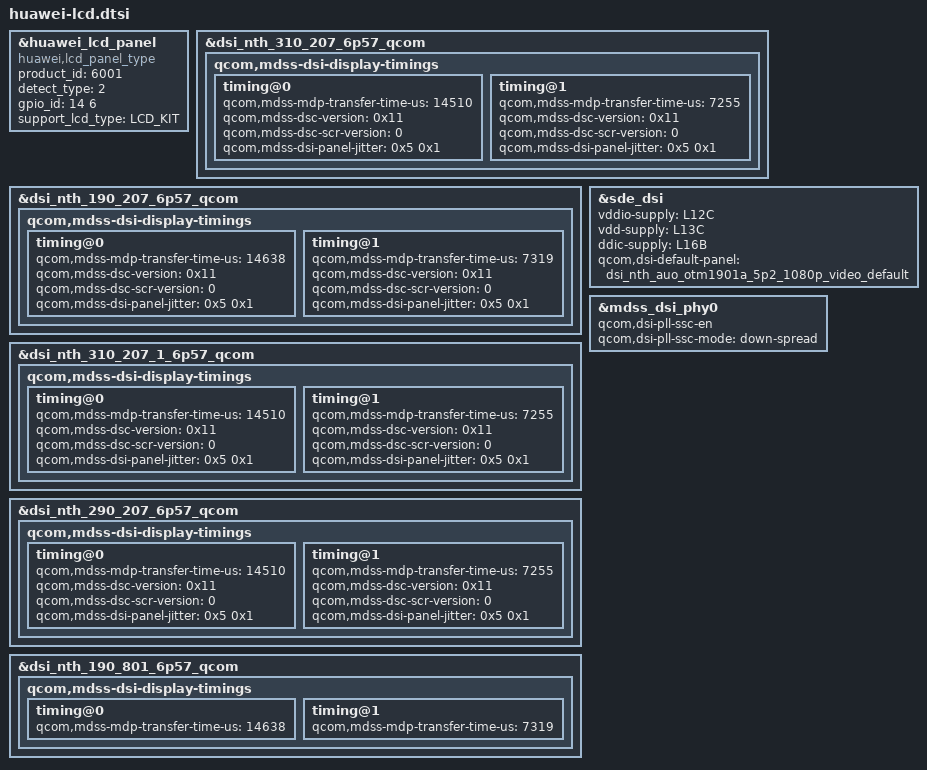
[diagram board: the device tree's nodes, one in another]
#include "../../../lcdkit3.0/nth/devkit_lcd_kit.dtsi"
&huawei_lcd_panel {
	compatible = "huawei,lcd_panel_type";
	/* auto_key_info @ name: product_id type: uint32 default: 0 */
	product_id = <6001>;
	detect_type = <2>;
	/* auto_key_info @ name: gpio_id[2] type: int default: 0 */
	gpio_id = <14 6>;
	support_lcd_type = "LCD_KIT";
};
&dsi_nth_310_207_6p57_qcom {
	qcom,mdss-dsi-display-timings {
		timing@0 {
			qcom,mdss-mdp-transfer-time-us = <14510>;
			qcom,mdss-dsc-version = <0x11>;
			qcom,mdss-dsc-scr-version = <0>;
			qcom,mdss-dsi-panel-jitter = <0x5 0x1>;
		};
		timing@1 {
			qcom,mdss-mdp-transfer-time-us = <7255>;
			qcom,mdss-dsc-version = <0x11>;
			qcom,mdss-dsc-scr-version = <0>;
			qcom,mdss-dsi-panel-jitter = <0x5 0x1>;
		};
	};
};
&dsi_nth_190_207_6p57_qcom {
	qcom,mdss-dsi-display-timings {
		timing@0 {
			qcom,mdss-mdp-transfer-time-us = <14638>;
			qcom,mdss-dsc-version = <0x11>;
			qcom,mdss-dsc-scr-version = <0>;
			qcom,mdss-dsi-panel-jitter = <0x5 0x1>;
		};
		timing@1 {
			qcom,mdss-mdp-transfer-time-us = <7319>;
			qcom,mdss-dsc-version = <0x11>;
			qcom,mdss-dsc-scr-version = <0>;
			qcom,mdss-dsi-panel-jitter = <0x5 0x1>;
		};
	};
};
&dsi_nth_310_207_1_6p57_qcom {
	qcom,mdss-dsi-display-timings {
		timing@0 {
			qcom,mdss-mdp-transfer-time-us = <14510>;
			qcom,mdss-dsc-version = <0x11>;
			qcom,mdss-dsc-scr-version = <0>;
			qcom,mdss-dsi-panel-jitter = <0x5 0x1>;
		};
		timing@1 {
			qcom,mdss-mdp-transfer-time-us = <7255>;
			qcom,mdss-dsc-version = <0x11>;
			qcom,mdss-dsc-scr-version = <0>;
			qcom,mdss-dsi-panel-jitter = <0x5 0x1>;
		};
	};
};
&dsi_nth_290_207_6p57_qcom {
	qcom,mdss-dsi-display-timings {
		timing@0 {
			qcom,mdss-mdp-transfer-time-us = <14510>;
			qcom,mdss-dsc-version = <0x11>;
			qcom,mdss-dsc-scr-version = <0>;
			qcom,mdss-dsi-panel-jitter = <0x5 0x1>;
		};
		timing@1 {
			qcom,mdss-mdp-transfer-time-us = <7255>;
			qcom,mdss-dsc-version = <0x11>;
			qcom,mdss-dsc-scr-version = <0>;
			qcom,mdss-dsi-panel-jitter = <0x5 0x1>;
		};
	};
};
&dsi_nth_190_801_6p57_qcom {
	qcom,mdss-dsi-display-timings {
		timing@0 {
			qcom,mdss-mdp-transfer-time-us = <14638>;
		};
		timing@1 {
			qcom,mdss-mdp-transfer-time-us = <7319>;
		};
	};
};
&sde_dsi {
	vddio-supply = <&L12C>;
	vdd-supply = <&L13C>;
	ddic-supply = <&L16B>;
	qcom,dsi-default-panel = <&dsi_nth_auo_otm1901a_5p2_1080p_video_default>;
};
&mdss_dsi_phy0 {
    qcom,dsi-pll-ssc-en;
    qcom,dsi-pll-ssc-mode = "down-spread";
};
